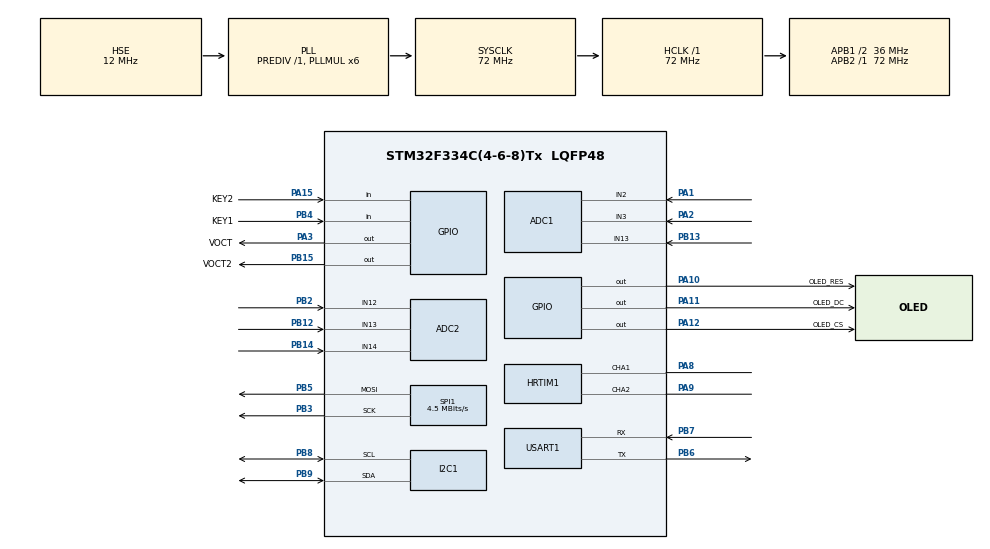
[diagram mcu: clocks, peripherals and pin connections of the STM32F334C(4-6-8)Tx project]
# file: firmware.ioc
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ADC1.Channel-0\#ChannelRegularConversion=ADC_CHANNEL_2
ADC1.Channel-1\#ChannelRegularConversion=ADC_CHANNEL_3
ADC1.Channel-2\#ChannelRegularConversion=ADC_CHANNEL_13
ADC1.Channel-3\#ChannelRegularConversion=ADC_CHANNEL_VREFINT
ADC1.ClockPrescaler=ADC_CLOCK_SYNC_PCLK_DIV4
ADC1.EOCSelection=ADC_EOC_SEQ_CONV
ADC1.NbrOfConversion=4
ADC1.NbrOfConversionFlag=1
ADC1.Offset-0\#ChannelRegularConversion=0
ADC1.Offset-1\#ChannelRegularConversion=0
ADC1.Offset-2\#ChannelRegularConversion=0
ADC1.Offset-3\#ChannelRegularConversion=0
ADC1.OffsetNumber-0\#ChannelRegularConversion=ADC_OFFSET_NONE
ADC1.OffsetNumber-1\#ChannelRegularConversion=ADC_OFFSET_NONE
ADC1.OffsetNumber-2\#ChannelRegularConversion=ADC_OFFSET_NONE
ADC1.OffsetNumber-3\#ChannelRegularConversion=ADC_OFFSET_NONE
ADC1.Rank-0\#ChannelRegularConversion=1
ADC1.Rank-1\#ChannelRegularConversion=2
ADC1.Rank-2\#ChannelRegularConversion=3
ADC1.Rank-3\#ChannelRegularConversion=4
ADC1.SamplingTime-0\#ChannelRegularConversion=ADC_SAMPLETIME_181CYCLES_5
ADC1.SamplingTime-1\#ChannelRegularConversion=ADC_SAMPLETIME_181CYCLES_5
ADC1.SamplingTime-2\#ChannelRegularConversion=ADC_SAMPLETIME_181CYCLES_5
ADC1.SamplingTime-3\#ChannelRegularConversion=ADC_SAMPLETIME_181CYCLES_5
ADC1.SamplingTimeOPAMP-3\#ChannelRegularConversion=ADC_SAMPLETIME_7CYCLES_5
ADC1.SequencerNbRanks=1
ADC1.SubFamily=STM32F334x8
ADC1.master=1
ADC2.Channel-0\#ChannelRegularConversion=ADC_CHANNEL_12
ADC2.Channel-1\#ChannelRegularConversion=ADC_CHANNEL_13
ADC2.Channel-2\#ChannelRegularConversion=ADC_CHANNEL_14
ADC2.ClockPrescaler=ADC_CLOCK_SYNC_PCLK_DIV4
ADC2.EOCSelection=ADC_EOC_SEQ_CONV
ADC2.NbrOfConversion=3
ADC2.NbrOfConversionFlag=1
ADC2.Offset-0\#ChannelRegularConversion=0
ADC2.Offset-1\#ChannelRegularConversion=0
ADC2.Offset-2\#ChannelRegularConversion=0
ADC2.OffsetNumber-0\#ChannelRegularConversion=ADC_OFFSET_NONE
ADC2.OffsetNumber-1\#ChannelRegularConversion=ADC_OFFSET_NONE
ADC2.OffsetNumber-2\#ChannelRegularConversion=ADC_OFFSET_NONE
ADC2.Rank-0\#ChannelRegularConversion=1
ADC2.Rank-1\#ChannelRegularConversion=2
ADC2.Rank-2\#ChannelRegularConversion=3
ADC2.SamplingTime-0\#ChannelRegularConversion=ADC_SAMPLETIME_181CYCLES_5
ADC2.SamplingTime-1\#ChannelRegularConversion=ADC_SAMPLETIME_181CYCLES_5
ADC2.SamplingTime-2\#ChannelRegularConversion=ADC_SAMPLETIME_181CYCLES_5
ADC2.SamplingTimeOPAMP-1\#ChannelRegularConversion=ADC_SAMPLETIME_7CYCLES_5
ADC2.SamplingTimeOPAMP-2\#ChannelRegularConversion=ADC_SAMPLETIME_7CYCLES_5
ADC2.SubFamily=STM32F334x8
Dma.ADC1.0.Direction=DMA_PERIPH_TO_MEMORY
Dma.ADC1.0.Instance=DMA1_Channel1
Dma.ADC1.0.MemDataAlignment=DMA_MDATAALIGN_HALFWORD
Dma.ADC1.0.MemInc=DMA_MINC_ENABLE
Dma.ADC1.0.Mode=DMA_NORMAL
Dma.ADC1.0.PeriphDataAlignment=DMA_PDATAALIGN_HALFWORD
Dma.ADC1.0.PeriphInc=DMA_PINC_DISABLE
Dma.ADC1.0.Priority=DMA_PRIORITY_LOW
Dma.ADC2.1.Direction=DMA_PERIPH_TO_MEMORY
Dma.ADC2.1.Instance=DMA1_Channel2
Dma.ADC2.1.MemDataAlignment=DMA_MDATAALIGN_HALFWORD
Dma.ADC2.1.MemInc=DMA_MINC_ENABLE
Dma.ADC2.1.Mode=DMA_NORMAL
Dma.ADC2.1.PeriphDataAlignment=DMA_PDATAALIGN_HALFWORD
Dma.ADC2.1.PeriphInc=DMA_PINC_DISABLE
Dma.ADC2.1.Priority=DMA_PRIORITY_LOW
Dma.Request0=ADC1
Dma.Request1=ADC2
Dma.Request2=SPI1_TX
Dma.Request3=USART1_RX
Dma.Request4=USART1_TX
Dma.SPI1_TX.2.Direction=DMA_MEMORY_TO_PERIPH
Dma.SPI1_TX.2.Instance=DMA1_Channel3
Dma.SPI1_TX.2.MemDataAlignment=DMA_MDATAALIGN_BYTE
Dma.SPI1_TX.2.MemInc=DMA_MINC_ENABLE
Dma.SPI1_TX.2.Mode=DMA_NORMAL
Dma.SPI1_TX.2.PeriphDataAlignment=DMA_PDATAALIGN_BYTE
Dma.SPI1_TX.2.PeriphInc=DMA_PINC_DISABLE
Dma.SPI1_TX.2.Priority=DMA_PRIORITY_LOW
Dma.USART1_RX.3.Direction=DMA_PERIPH_TO_MEMORY
Dma.USART1_RX.3.Instance=DMA1_Channel5
Dma.USART1_RX.3.MemDataAlignment=DMA_MDATAALIGN_BYTE
Dma.USART1_RX.3.MemInc=DMA_MINC_ENABLE
Dma.USART1_RX.3.Mode=DMA_NORMAL
Dma.USART1_RX.3.PeriphDataAlignment=DMA_PDATAALIGN_BYTE
Dma.USART1_RX.3.PeriphInc=DMA_PINC_DISABLE
Dma.USART1_RX.3.Priority=DMA_PRIORITY_LOW
Dma.USART1_TX.4.Direction=DMA_MEMORY_TO_PERIPH
Dma.USART1_TX.4.Instance=DMA1_Channel4
Dma.USART1_TX.4.MemDataAlignment=DMA_MDATAALIGN_BYTE
Dma.USART1_TX.4.MemInc=DMA_MINC_ENABLE
Dma.USART1_TX.4.Mode=DMA_NORMAL
Dma.USART1_TX.4.PeriphDataAlignment=DMA_PDATAALIGN_BYTE
Dma.USART1_TX.4.PeriphInc=DMA_PINC_DISABLE
Dma.USART1_TX.4.Priority=DMA_PRIORITY_LOW
HRTIM1.CompareUnit1-Output_TA1TA2=HRTIM_COMPAREUNIT_1
HRTIM1.CompareValue1-Output_TA1TA2=20000
HRTIM1.DeadTimeInsertion-Output_TA1TA2=HRTIM_TIMDEADTIMEINSERTION_ENABLED
HRTIM1.FallingValue-Output_TA1TA2=120
HRTIM1.HalfModeEnable-Output_TA1TA2=HRTIM_HALFMODE_DISABLED
HRTIM1.NumberResetSource1-Output_TA1TA2=1
HRTIM1.NumberSetSource1-Output_TA1TA2=1
HRTIM1.Periode_TA=15360
HRTIM1.Polarity1-Output_TA1TA2=HRTIM_OUTPUTPOLARITY_HIGH
HRTIM1.Polarity2-Output_TA1TA2=HRTIM_OUTPUTPOLARITY_HIGH
HRTIM1.PreloadEnable-Output_TA1TA2=HRTIM_PRELOAD_ENABLED
HRTIM1.PrescalerDead-Output_TA1TA2=HRTIM_TIMDEADTIME_PRESCALERRATIO_MUL4
HRTIM1.RepetitionUpdate-Output_TA1TA2=HRTIM_UPDATEONREPETITION_ENABLED
HRTIM1.ResetOutput1_Source1-Output_TA1TA2=HRTIM_OUTPUTRESET_TIMCMP1
HRTIM1.RisingValue-Output_TA1TA2=120
HRTIM1.SetOutput1_Source1-Output_TA1TA2=HRTIM_OUTPUTSET_TIMPER
Mcu.Family=STM32F3
Mcu.Name=STM32F334C(4-6-8)Tx
Mcu.Package=LQFP48
NVIC.ADC1_2_IRQn=true\:2\:0\:true\:false\:true\:true\:true\:true
NVIC.DMA1_Channel1_IRQn=true\:0\:0\:false\:false\:true\:false\:true\:true
NVIC.DMA1_Channel2_IRQn=true\:0\:0\:false\:false\:true\:false\:true\:true
NVIC.DMA1_Channel3_IRQn=true\:3\:0\:true\:false\:true\:false\:true\:true
NVIC.DMA1_Channel4_IRQn=true\:0\:0\:false\:false\:true\:false\:true\:true
NVIC.DMA1_Channel5_IRQn=true\:0\:0\:false\:false\:true\:false\:true\:true
NVIC.I2C1_ER_IRQn=true\:3\:0\:true\:false\:true\:true\:true\:true
NVIC.I2C1_EV_IRQn=true\:3\:0\:true\:false\:true\:true\:true\:true
NVIC.PriorityGroup=NVIC_PRIORITYGROUP_4
NVIC.SPI1_IRQn=true\:3\:0\:true\:false\:true\:true\:true\:true
NVIC.TIM3_IRQn=true\:1\:0\:true\:false\:true\:true\:true\:true
NVIC.USART1_IRQn=true\:3\:0\:true\:false\:true\:true\:true\:true
PA0.Mode=SYS_WakeUp0
PA0.Signal=SYS_WKUP1
PA1.Mode=IN2-Single-Ended
PA1.Signal=ADC1_IN2
PA10.GPIO_Label=OLED_RES
PA10.GPIO_Speed=GPIO_SPEED_FREQ_HIGH
PA10.Signal=GPIO_Output
PA11.GPIO_Label=OLED_DC
PA11.GPIO_Speed=GPIO_SPEED_FREQ_HIGH
PA11.Signal=GPIO_Output
PA12.GPIO_Label=OLED_CS
PA12.GPIO_Speed=GPIO_SPEED_FREQ_HIGH
PA12.Signal=GPIO_Output
PA13.Mode=Serial_Wire
PA13.Signal=SYS_JTMS-SWDIO
PA14.Mode=Serial_Wire
PA14.Signal=SYS_JTCK-SWCLK
PA15.GPIO_Label=KEY2
PA15.GPIO_PuPd=GPIO_PULLUP
PA15.Signal=GPIO_Input
PA2.Mode=IN3-Single-Ended
PA2.Signal=ADC1_IN3
PA3.GPIO_Label=VOCT
PA3.PinState=GPIO_PIN_SET
PA3.Signal=GPIO_Output
PA8.Mode=Output_TA1TA2
PA8.Signal=HRTIM1_CHA1
PA9.Mode=Output_TA1TA2
PA9.Signal=HRTIM1_CHA2
PB12.Mode=IN13-Single-Ended
PB12.Signal=ADC2_IN13
PB13.Mode=IN13-Single-Ended
PB13.Signal=ADC1_IN13
PB14.Mode=IN14-Single-Ended
PB14.Signal=ADC2_IN14
PB15.GPIO_Label=VOCT2
PB15.GPIO_ModeDefaultOutputPP=GPIO_MODE_OUTPUT_OD
PB15.GPIO_PuPd=GPIO_NOPULL
PB15.Signal=GPIO_Output
PB2.Mode=IN12-Single-Ended
PB2.Signal=ADC2_IN12
PB3.Mode=TX_Only_Simplex_Unidirect_Master
PB3.Signal=SPI1_SCK
PB4.GPIO_Label=KEY1
PB4.GPIO_PuPd=GPIO_PULLUP
PB4.Signal=GPIO_Input
PB5.Mode=TX_Only_Simplex_Unidirect_Master
PB5.Signal=SPI1_MOSI
PB6.Mode=Asynchronous
PB6.Signal=USART1_TX
PB7.Mode=Asynchronous
PB7.Signal=USART1_RX
PB8.Mode=I2C
PB8.Signal=I2C1_SCL
PB9.Mode=I2C
PB9.Signal=I2C1_SDA
PC13.Mode=SYS_WakeUp1
PC13.Signal=SYS_WKUP2
PF0\ /\ OSC_IN.Mode=HSE-External-Oscillator
PF0\ /\ OSC_IN.Signal=RCC_OSC_IN
PF1\ /\ OSC_OUT.Mode=HSE-External-Oscillator
PF1\ /\ OSC_OUT.Signal=RCC_OSC_OUT
ProjectManager.HeapSize=0x200
ProjectManager.StackSize=0x400
ProjectManager.TargetToolchain=Makefile
RCC.AHBFreq_Value=72000000
RCC.APB1CLKDivider=RCC_HCLK_DIV2
RCC.APB1Freq_Value=36000000
RCC.APB1TimFreq_Value=72000000
RCC.APB2Freq_Value=72000000
RCC.APB2TimFreq_Value=72000000
RCC.CortexFreq_Value=72000000
RCC.HCLKFreq_Value=72000000
RCC.HRTIMSelection=RCC_HRTIM1CLK_PLLCLK
RCC.HSE_VALUE=12000000
RCC.HSI_VALUE=8000000
RCC.LSE_VALUE=32768
RCC.PLLMUL=RCC_PLL_MUL6
RCC.PLLSourceVirtual=RCC_PLLSOURCE_HSE
RCC.SYSCLKFreq_VALUE=72000000
RCC.SYSCLKSourceVirtual=RCC_SYSCLKSOURCE_PLLCLK
SPI1.BaudRatePrescaler=SPI_BAUDRATEPRESCALER_16
SPI1.CalculateBaudRate=4.5 MBits/s
SPI1.DataSize=SPI_DATASIZE_8BIT
SPI1.Direction=SPI_DIRECTION_2LINES
SPI1.Mode=SPI_MODE_MASTER
SPI1.NSSPMode=SPI_NSS_PULSE_DISABLE
SPI1.VirtualType=VM_MASTER
STMicroelectronics.X-CUBE-ALGOBUILD.1.3.0.LibraryCcDSPOoLibraryJjDSPOoLibrary=true
TIM3.Period=49
TIM3.Prescaler=71
USART1.VirtualMode-Asynchronous=VM_ASYNC
VP_ADC1_Vref_Input.Mode=IN-Vrefint
VP_STMicroelectronics.X-CUBE-ALGOBUILD_VS_DSPOoLibraryJjLibrary_1.3.0_1.3.0.Mode=DSPOoLibraryJjLibrary
VP_TIM3_VS_ClockSourceINT.Mode=Internal
board=custom

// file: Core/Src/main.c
/* USER CODE BEGIN Header */
/**
  ******************************************************************************
  * @file           : main.c
  * @brief          : Main program body
  ******************************************************************************
  * @attention
  *
  * Copyright (c) 2023 STMicroelectronics.
  * All rights reserved.
  *
  * This software is licensed under terms that can be found in the LICENSE file
  * in the root directory of this software component.
  * If no LICENSE file comes with this software, it is provided AS-IS.
  *
  ******************************************************************************
  */
/* USER CODE END Header */
#include "main.h"
#include "adc.h"
#include "dma.h"
#include "hrtim.h"
#include "i2c.h"
#include "spi.h"
#include "tim.h"
#include "usart.h"
#include "gpio.h"

/* USER CODE BEGIN Includes */
#include "user_main.h"
/* USER CODE END Includes */

void SystemClock_Config(void);

int main(void)
{

  /* MCU Configuration--------------------------------------------------------*/

  /* Reset of all peripherals, Initializes the Flash interface and the Systick. */
  HAL_Init();

  /* Configure the system clock */
  SystemClock_Config();

  /* Initialize all configured peripherals */
  MX_GPIO_Init();
  MX_DMA_Init();
  MX_HRTIM1_Init();
  MX_SPI1_Init();
  MX_ADC1_Init();
  MX_ADC2_Init();
  MX_I2C1_Init();
  MX_USART1_UART_Init();
  MX_TIM3_Init();
  /* USER CODE BEGIN 2 */
  user_main();
  /* USER CODE END 2 */

  /* Infinite loop */
  while (1)
  {

    /* USER CODE BEGIN 3 */
    Task_Pro_Handler_Callback();
  }
  /* USER CODE END 3 */
}

void SystemClock_Config(void)
{
  RCC_OscInitTypeDef RCC_OscInitStruct = {0};
  RCC_ClkInitTypeDef RCC_ClkInitStruct = {0};
  RCC_PeriphCLKInitTypeDef PeriphClkInit = {0};

  /** Initializes the RCC Oscillators according to the specified parameters
  * in the RCC_OscInitTypeDef structure.
  */
  RCC_OscInitStruct.OscillatorType = RCC_OSCILLATORTYPE_HSI|RCC_OSCILLATORTYPE_HSE;
  RCC_OscInitStruct.HSEState = RCC_HSE_ON;
  RCC_OscInitStruct.HSEPredivValue = RCC_HSE_PREDIV_DIV1;
  RCC_OscInitStruct.HSIState = RCC_HSI_ON;
  RCC_OscInitStruct.HSICalibrationValue = RCC_HSICALIBRATION_DEFAULT;
  RCC_OscInitStruct.PLL.PLLState = RCC_PLL_ON;
  RCC_OscInitStruct.PLL.PLLSource = RCC_PLLSOURCE_HSE;
  RCC_OscInitStruct.PLL.PLLMUL = RCC_PLL_MUL6;
  if (HAL_RCC_OscConfig(&RCC_OscInitStruct) != HAL_OK)
  {
    Error_Handler();
  }

  /** Initializes the CPU, AHB and APB buses clocks
  */
  RCC_ClkInitStruct.ClockType = RCC_CLOCKTYPE_HCLK|RCC_CLOCKTYPE_SYSCLK
                              |RCC_CLOCKTYPE_PCLK1|RCC_CLOCKTYPE_PCLK2;
  RCC_ClkInitStruct.SYSCLKSource = RCC_SYSCLKSOURCE_PLLCLK;
  RCC_ClkInitStruct.AHBCLKDivider = RCC_SYSCLK_DIV1;
  RCC_ClkInitStruct.APB1CLKDivider = RCC_HCLK_DIV2;
  RCC_ClkInitStruct.APB2CLKDivider = RCC_HCLK_DIV1;

  if (HAL_RCC_ClockConfig(&RCC_ClkInitStruct, FLASH_LATENCY_2) != HAL_OK)
  {
    Error_Handler();
  }
  PeriphClkInit.PeriphClockSelection = RCC_PERIPHCLK_HRTIM1|RCC_PERIPHCLK_USART1
                              |RCC_PERIPHCLK_I2C1;
  PeriphClkInit.Usart1ClockSelection = RCC_USART1CLKSOURCE_PCLK1;
  PeriphClkInit.I2c1ClockSelection = RCC_I2C1CLKSOURCE_HSI;
  PeriphClkInit.Hrtim1ClockSelection = RCC_HRTIM1CLK_PLLCLK;
  if (HAL_RCCEx_PeriphCLKConfig(&PeriphClkInit) != HAL_OK)
  {
    Error_Handler();
  }
}

void Error_Handler(void)
{
  __disable_irq();
  while (1)
  {
  }
}
